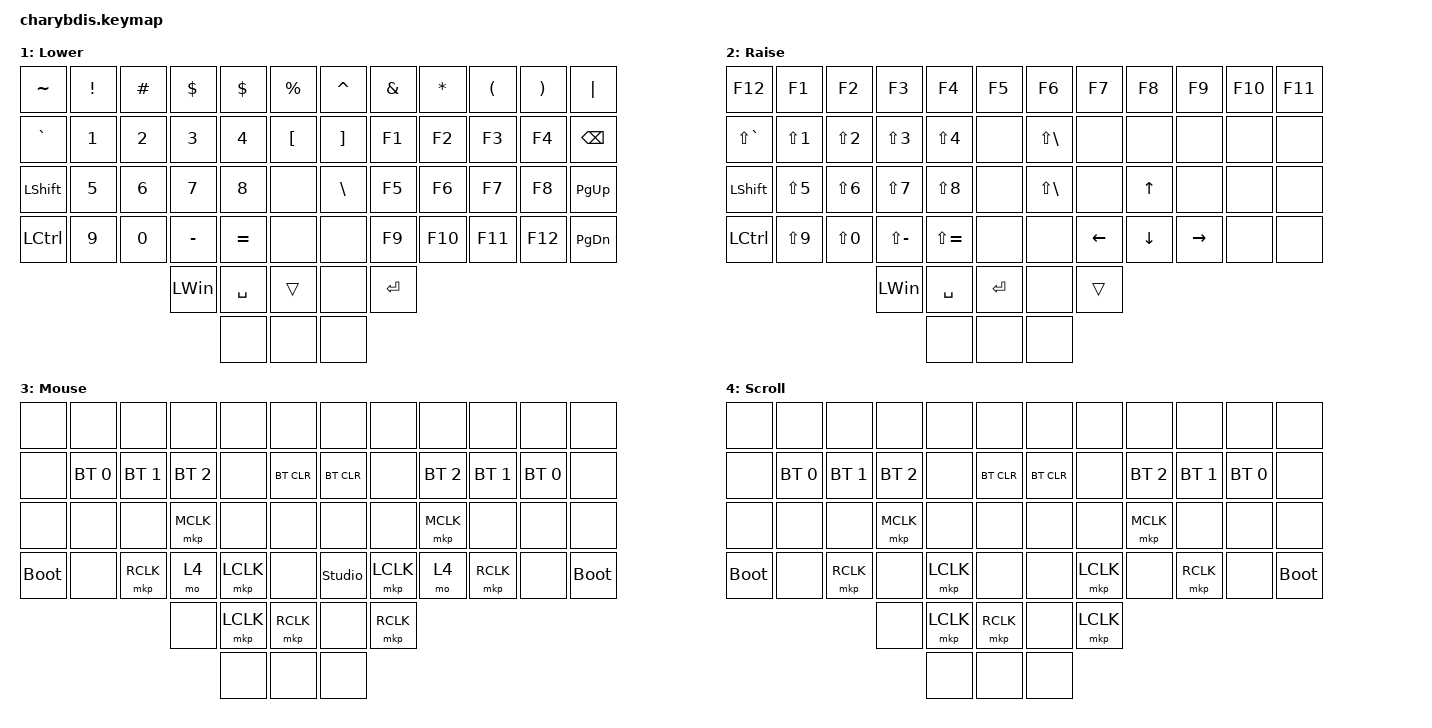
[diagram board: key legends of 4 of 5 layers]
#include <behaviors.dtsi>
#include <dt-bindings/zmk/keys.h>
#include <dt-bindings/zmk/bt.h>
#include <dt-bindings/zmk/mouse.h>
#include <dt-bindings/zmk/pointing.h>

&lt {
    tapping-term-ms = <200>;
    flavor = "balanced";
    quick-tap-ms = <150>;
};

/ {
    combos { compatible = "zmk,combos"; };

    keymap {
        compatible = "zmk,keymap";

        Base {
            bindings = <
&kp GRAVE       &kp N1   &kp N2  &kp N3        &kp N4        &kp N5          &kp N6       &kp N7         &kp N8     &kp N9   &kp N0       &kp BACKSLASH
&kp TAB         &kp Q    &kp W   &kp E         &kp R         &kp T           &kp Y        &kp U          &kp I      &kp O    &kp P        &kp BACKSPACE
&kp LEFT_SHIFT  &kp A    &kp S   &kp D         &kp F         &kp G           &kp H        &kp J          &kp K      &kp L    &kp SEMI     &kp APOS
&kp LCTRL       &lt 3 Z  &kp X   &kp C         &kp V         &kp B           &kp N        &kp M          &kp COMMA  &kp DOT  &lt 3 SLASH  &kp ESCAPE
                                 &kp LEFT_WIN  &kp SPACE     &lt 1 ENTER     &kp LEFT_ALT &lt 2 ENTER
                                               &kp CAPSLOCK  &kp LEFT_ALT    &kp DELETE   &none
            >;
            sensor-bindings = <&inc_dec_kp UP DOWN>;
        };

        Lower {
            bindings = <
&kp TILDE  &kp EXCLAMATION  &kp HASH      &kp DOLLAR    &kp DOLLAR    &kp PERCENT    &kp CARET      &kp AMPERSAND  &kp ASTERISK  &kp LEFT_PARENTHESIS  &kp RIGHT_PARENTHESIS  &kp PIPE
&kp GRAVE  &kp N1           &kp N2        &kp N3        &kp N4        &kp LBKT       &kp RBKT       &kp F1         &kp F2        &kp F3                &kp F4                 &kp BACKSPACE
&kp LSHFT  &kp N5           &kp N6        &kp N7        &kp N8        &none          &kp BACKSLASH  &kp F5         &kp F6        &kp F7                &kp F8                 &kp PAGE_UP
&kp LCTRL  &kp N9           &kp N0        &kp MINUS     &kp EQUAL     &none          &none          &kp F9         &kp F10       &kp F11               &kp F12                &kp PAGE_DOWN
                                          &kp LEFT_WIN  &kp SPACE     &trans         &none          &kp ENTER
                                                        &none         &none          &none
            >;
            sensor-bindings = <&inc_dec_kp UP DOWN>;
        };

        Raise {
            bindings = <
&kp F12        &kp F1      &kp F2      &kp F3         &kp F4         &kp F5          &kp F6             &kp F7         &kp F8    &kp F9     &kp F10  &kp F11
&kp LS(GRAVE)  &kp LS(N1)  &kp LS(N2)  &kp LS(N3)     &kp LS(N4)     &none           &kp LS(BACKSLASH)  &none          &none     &none      &none    &none
&kp LSHFT      &kp LS(N5)  &kp LS(N6)  &kp LS(N7)     &kp LS(N8)     &none           &kp LS(BACKSLASH)  &none          &kp UP    &none      &none    &none
&kp LCTRL      &kp LS(N9)  &kp LS(N0)  &kp LS(MINUS)  &kp LS(EQUAL)  &none           &none              &kp LEFT       &kp DOWN  &kp RIGHT  &none    &none
                                       &kp LEFT_WIN   &kp SPACE      &kp ENTER       &none              &trans
                                                      &none          &none           &none
            >;
        };

        Mouse {
            bindings = <
&none        &none         &none         &none         &none      &none         &none           &none      &none         &none         &none         &none
&none        &bt BT_SEL 0  &bt BT_SEL 1  &bt BT_SEL 2  &none      &bt BT_CLR    &bt BT_CLR      &none      &bt BT_SEL 2  &bt BT_SEL 1  &bt BT_SEL 0  &none
&none        &none         &none         &mkp MCLK     &none      &none         &none           &none      &mkp MCLK     &none         &none         &none
&bootloader  &none         &mkp RCLK     &mo 4         &mkp LCLK  &none         &studio_unlock  &mkp LCLK  &mo 4         &mkp RCLK     &none         &bootloader
                                         &none         &mkp LCLK  &mkp RCLK     &none           &mkp RCLK
                                                       &none      &none         &none
            >;
            sensor-bindings = <&inc_dec_kp C_VOL_UP C_VOL_DN>;
        };

        Scroll {
            bindings = <
&none        &none         &none         &none         &none      &none         &none       &none      &none         &none         &none         &none
&none        &bt BT_SEL 0  &bt BT_SEL 1  &bt BT_SEL 2  &none      &bt BT_CLR    &bt BT_CLR  &none      &bt BT_SEL 2  &bt BT_SEL 1  &bt BT_SEL 0  &none
&none        &none         &none         &mkp MCLK     &none      &none         &none       &none      &mkp MCLK     &none         &none         &none
&bootloader  &none         &mkp RCLK     &none         &mkp LCLK  &none         &none       &mkp LCLK  &none         &mkp RCLK     &none         &bootloader
                                         &none         &mkp LCLK  &mkp RCLK     &none       &mkp LCLK
                                                       &none      &none         &none
            >;
        };
    };
};
